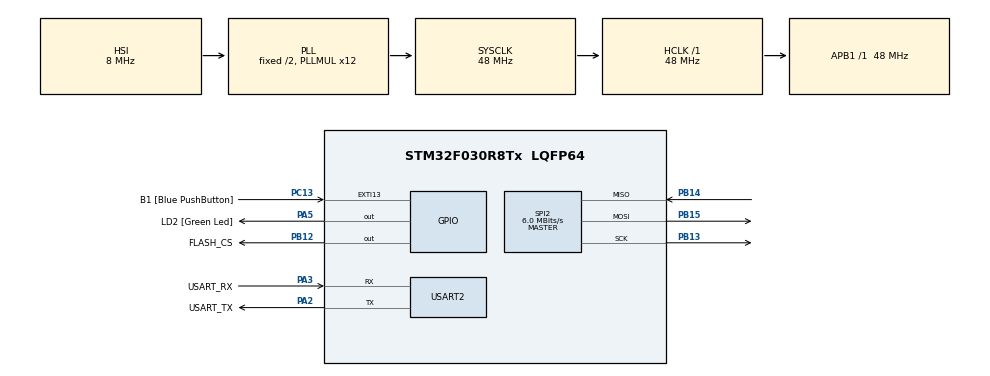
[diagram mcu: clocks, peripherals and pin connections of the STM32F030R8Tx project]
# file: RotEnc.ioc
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Mcu.Family=STM32F0
Mcu.Name=STM32F030R8Tx
Mcu.Package=LQFP64
PA13.GPIO_Label=TMS
PA13.Mode=Serial_Wire
PA13.Signal=SYS_SWDIO
PA14.GPIO_Label=TCK
PA14.Mode=Serial_Wire
PA14.Signal=SYS_SWCLK
PA2.GPIO_Label=USART_TX
PA2.GPIO_Mode=GPIO_MODE_AF_PP
PA2.GPIO_PuPd=GPIO_NOPULL
PA2.GPIO_Speed=GPIO_SPEED_FREQ_LOW
PA2.Mode=Asynchronous
PA2.Signal=USART2_TX
PA3.GPIO_Label=USART_RX
PA3.GPIO_Mode=GPIO_MODE_AF_PP
PA3.GPIO_PuPd=GPIO_NOPULL
PA3.GPIO_Speed=GPIO_SPEED_FREQ_LOW
PA3.Mode=Asynchronous
PA3.Signal=USART2_RX
PA5.GPIO_Label=LD2 [Green Led]
PA5.GPIO_Mode=GPIO_MODE_OUTPUT_PP
PA5.GPIO_PuPd=GPIO_NOPULL
PA5.GPIO_Speed=GPIO_SPEED_FREQ_LOW
PA5.Signal=GPIO_Output
PB12.GPIO_Label=FLASH_CS
PB12.Signal=GPIO_Output
PB13.Mode=Full_Duplex_Master
PB13.Signal=SPI2_SCK
PB14.Mode=Full_Duplex_Master
PB14.Signal=SPI2_MISO
PB15.Mode=Full_Duplex_Master
PB15.Signal=SPI2_MOSI
PC13.GPIO_Label=B1 [Blue PushButton]
PC13.GPIO_ModeDefaultEXTI=GPIO_MODE_IT_FALLING
PC13.Signal=GPXTI13
PC14-OSC32_IN.Mode=LSE-External-Oscillator
PC14-OSC32_IN.Signal=RCC_OSC32_IN
PC15-OSC32_OUT.Mode=LSE-External-Oscillator
PC15-OSC32_OUT.Signal=RCC_OSC32_OUT
PF0-OSC_IN.Mode=HSE-External-Clock-Source
PF0-OSC_IN.Signal=RCC_OSC_IN
PF1-OSC_OUT.Signal=RCC_OSC_OUT
ProjectManager.HeapSize=0x200
ProjectManager.StackSize=0x400
ProjectManager.TargetToolchain=STM32CubeIDE
RCC.AHBFreq_Value=48000000
RCC.APB1Freq_Value=48000000
RCC.APB1TimFreq_Value=48000000
RCC.HCLKFreq_Value=48000000
RCC.PLLMUL=RCC_PLL_MUL12
RCC.SYSCLKFreq_VALUE=48000000
RCC.SYSCLKSource=RCC_SYSCLKSOURCE_PLLCLK
SPI2.BaudRatePrescaler=SPI_BAUDRATEPRESCALER_8
SPI2.CalculateBaudRate=6.0 MBits/s
SPI2.DataSize=SPI_DATASIZE_8BIT
SPI2.Direction=SPI_DIRECTION_2LINES
SPI2.Mode=SPI_MODE_MASTER
SPI2.VirtualType=VM_MASTER
USART2.VirtualMode-Asynchronous=VM_ASYNC
board=NUCLEO-F030R8

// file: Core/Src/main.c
/* USER CODE BEGIN Header */
/**
  ******************************************************************************
  * @file           : main.c
  * @brief          : Main program body
  ******************************************************************************
  * @attention
  *
  * <h2><center>&copy; Copyright (c) 2022 STMicroelectronics.
  * All rights reserved.</center></h2>
  *
  * This software component is licensed by ST under BSD 3-Clause license,
  * the "License"; You may not use this file except in compliance with the
  * License. You may obtain a copy of the License at:
  *                        opensource.org/licenses/BSD-3-Clause
  *
  ******************************************************************************
  */
/* USER CODE END Header */
#include "main.h"
#include "spi.h"
#include "usart.h"
#include "gpio.h"

/* USER CODE BEGIN Includes */
#include "w25qxx.h"
#include "w25qxxConf.h"

/* USER CODE END Includes */

void SystemClock_Config(void);

int main(void)
{
  /* USER CODE BEGIN 1 */
	uint8_t writeBuffer[8] = { 1, 2, 3, 4, 5, 6, 7, 8};
	uint8_t readBuffer[8];
	bool isInit = false;
  /* USER CODE END 1 */

  /* MCU Configuration--------------------------------------------------------*/

  /* Reset of all peripherals, Initializes the Flash interface and the Systick. */
  HAL_Init();

  /* Configure the system clock */
  SystemClock_Config();

  /* Initialize all configured peripherals */
  MX_GPIO_Init();
  MX_USART2_UART_Init();
  MX_SPI2_Init();
  /* USER CODE BEGIN 2 */
  isInit = W25qxx_Init();
  W25qxx_EraseSector(1);
  W25qxx_WriteSector(writeBuffer, 1, 0, 8);
  W25qxx_ReadSector(readBuffer, 1, 0, 8);

  /* USER CODE END 2 */

  /* Infinite loop */
  while (1)
  {

  }
}

void SystemClock_Config(void)
{
  RCC_OscInitTypeDef RCC_OscInitStruct = {0};
  RCC_ClkInitTypeDef RCC_ClkInitStruct = {0};

  /** Initializes the RCC Oscillators according to the specified parameters
  * in the RCC_OscInitTypeDef structure.
  */
  RCC_OscInitStruct.OscillatorType = RCC_OSCILLATORTYPE_HSI;
  RCC_OscInitStruct.HSIState = RCC_HSI_ON;
  RCC_OscInitStruct.HSICalibrationValue = RCC_HSICALIBRATION_DEFAULT;
  RCC_OscInitStruct.PLL.PLLState = RCC_PLL_ON;
  RCC_OscInitStruct.PLL.PLLSource = RCC_PLLSOURCE_HSI;
  RCC_OscInitStruct.PLL.PLLMUL = RCC_PLL_MUL12;
  RCC_OscInitStruct.PLL.PREDIV = RCC_PREDIV_DIV1;
  if (HAL_RCC_OscConfig(&RCC_OscInitStruct) != HAL_OK)
  {
    Error_Handler();
  }
  /** Initializes the CPU, AHB and APB buses clocks
  */
  RCC_ClkInitStruct.ClockType = RCC_CLOCKTYPE_HCLK|RCC_CLOCKTYPE_SYSCLK
                              |RCC_CLOCKTYPE_PCLK1;
  RCC_ClkInitStruct.SYSCLKSource = RCC_SYSCLKSOURCE_PLLCLK;
  RCC_ClkInitStruct.AHBCLKDivider = RCC_SYSCLK_DIV1;
  RCC_ClkInitStruct.APB1CLKDivider = RCC_HCLK_DIV1;

  if (HAL_RCC_ClockConfig(&RCC_ClkInitStruct, FLASH_LATENCY_1) != HAL_OK)
  {
    Error_Handler();
  }
}

void Error_Handler(void)
{
}

/************************ (C) COPYRIGHT STMicroelectronics *****END OF FILE****/
